# STM32H7B0xxQ register map
File version: 1.0
Registers are 32-bit, read-write, reset 0x0 unless marked. A register's access mark holds for its fields unless they carry their own. Offsets are from the block's base; [hi:lo] are bit positions; {n}, {i} and the like mark numbered series.

## SYSCFG — System configuration controller
Base 0x58000400
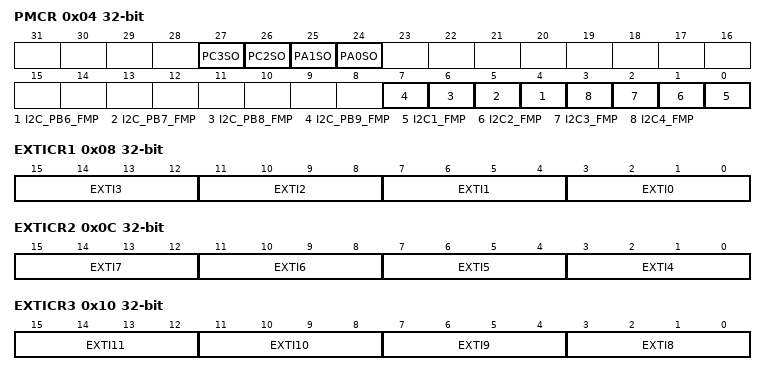
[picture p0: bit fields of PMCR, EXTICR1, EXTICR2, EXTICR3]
0x04 PMCR — SYSCFG peripheral mode configuration register
  [27] PC3SO — PC3 Switch Open
  [26] PC2SO — PC2 Switch Open
  [25] PA1SO — PA1 Switch Open
  [24] PA0SO — PA0 Switch Open
  [n-2] I2C_PB{n}_FMP (n=6..9) — I2C PB{n} Fast mode plus
  [n-1] I2C{n}_FMP (n=1..4) — I2C{n} Fast mode plus
0x08 EXTICR1 — SYSCFG external interrupt configuration registers
  [4n+3:4n] EXTI{n} (n=0..3) — EXTI {n} configuration
0x0C EXTICR2 — SYSCFG external interrupt configuration registers
  [4n-13:4n-16] EXTI{n} (n=4..7) — EXTI {n} configuration
0x10 EXTICR3 — SYSCFG external interrupt configuration registers
  [4n-29:4n-32] EXTI{n} (n=8..11) — EXTI {n} configuration
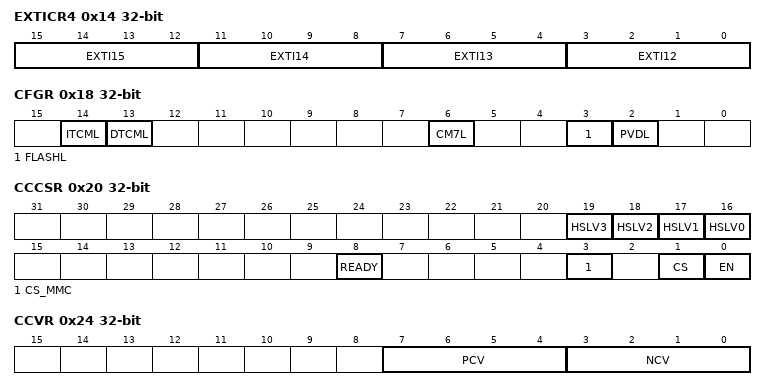
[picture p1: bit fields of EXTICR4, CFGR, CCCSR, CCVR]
0x14 EXTICR4 — SYSCFG external interrupt configuration registers
  [4n-45:4n-48] EXTI{n} (n=12..15) — EXTI {n} configuration
0x18 CFGR — SYSCFG configuration registers
  [14] ITCML — ITCM double ECC error lock bit
  [13] DTCML — DTCM double ECC error lock bit
  [6] CM7L — Cortex-M7 LOCKUP (Hardfault) output enable bit
  [3] FLASHL — FLASH double ECC error lock bit
  [2] PVDL — PVD lock enable bit
0x20 CCCSR — SYSCFG compensation cell control/status register
  [n+16] HSLV{n} (n=0..3) — High-speed at low-voltage
  [8] READY — I/O compensation cell ready flag
  [3] CS_MMC — I/O compensation cell code selection
  [1] CS — I/O compensation cell code selection
  [0] EN — I/O compensation cell enable
0x24 CCVR — SYSCFG compensation cell value register
  [7:4] PCV — PMOS compensation value
  [3:0] NCV — NMOS compensation value
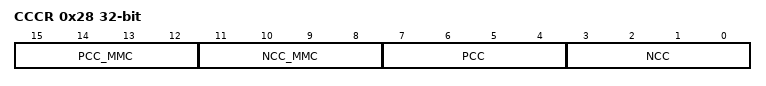
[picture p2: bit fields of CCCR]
0x28 CCCR — SYSCFG compensation cell code register
  [15:12] PCC_MMC — PMOS compensation code
  [11:8] NCC_MMC — NMOS compensation code
  [7:4] PCC — PMOS compensation code
  [3:0] NCC — NMOS compensation code

## COMP12 — Comparator
Base 0x58003800
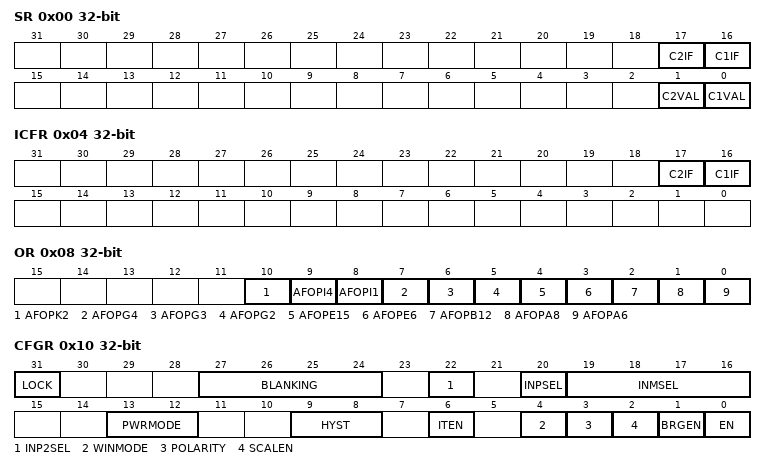
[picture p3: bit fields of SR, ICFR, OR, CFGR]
0x00 SR — Comparator status register
  [17] C2IF, [16] C1IF, [1] C2VAL, [0] C1VAL
0x04 ICFR — Comparator interrupt clear flag register
  [17] C2IF, [16] C1IF
0x08 OR — Comparator option register
  [10] AFOPK2, [9] AFOPI4, [8] AFOPI1, [7] AFOPG4, [6] AFOPG3, [5] AFOPG2, [4] AFOPE15, [3] AFOPE6, [2] AFOPB12, [1] AFOPA8, [0] AFOPA6
0x10 CFGR — COMP control and status register, used for bits common to several COMP instances
  [31] LOCK — COMPx Lock Bit
  [27:24] BLANKING — COMPx blanking source selection bits
    0=NONE (Comparator output without blanking); 1=TIM1_OC5 (Comparator output blanking source TIM1 OC5 (common to all COMP instances: COMP1, COMP2)); 2=TIM2_OC3 (Comparator output blanking source TIM2 OC3 (common to all COMP instances: COMP1, COMP2)); 3=TIM3_OC3 (Comparator output blanking source TIM3 OC3 (common to all COMP instances: COMP1, COMP2)); 4=TIM3_OC4 (Comparator output blanking source TIM3 OC4 (common to all COMP instances: COMP1, COMP2)); 5=TIM8_OC5 (Comparator output blanking source TIM8 OC5 (common to all COMP instances: COMP1, COMP2)); 6=TIM15_OC1 (Comparator output blanking source TIM15 OC1 (common to all COMP instances: COMP1, COMP2))
  [22] INP2SEL — COMPx input plus 2 selection bit
  [20] INPSEL — COMPx input plus selection bit
  [19:16] INMSEL — COMPx input minus selection bit
  [13:12] PWRMODE — COMPx Power Mode of the comparator
    0=HIGHSPEED (COMP power mode to high speed); 1=MEDIUMSPEED (COMP power mode to medium speed); 3=ULTRALOWPOWER (COMP power mode to ultra-low power)
  [9:8] HYST — COMPx hysteresis selection bits
    0=NONE (No hysteresis); 1=LOW (Hysteresis level low); 2=MEDIUM (Hysteresis level medium); 3=HIGH (Hysteresis level high)
  [6] ITEN — COMPx interrupt enable
  [4] WINMODE — COMPx Windows mode selection bit
    0=DISABLE (Window mode disable: Comparators 1 and 2 are independent); 1=COMP1_INPUT_PLUS_COMMON (Window mode enable: Comparators instances pair COMP1 and COMP2 have their input plus connected together. The common input is COMP1 input plus (COMP2 input plus is no more accessible).)
  [3] POLARITY — COMPx polarity selection bit
    0=NONINVERTED (COMP output polarity is not inverted: comparator output is high when the plus (non-inverting) input is at a higher voltage than the minus (inverting) input); 1=INVERTED (COMP output polarity is inverted: comparator output is low when the plus (non-inverting) input is at a lower voltage than the minus (inverting) input)
  [2] SCALEN — COMPx Voltage scaler enable bit
  [1] BRGEN — COMPx Scaler bridge enable
  [0] EN — COMPx enable bit
